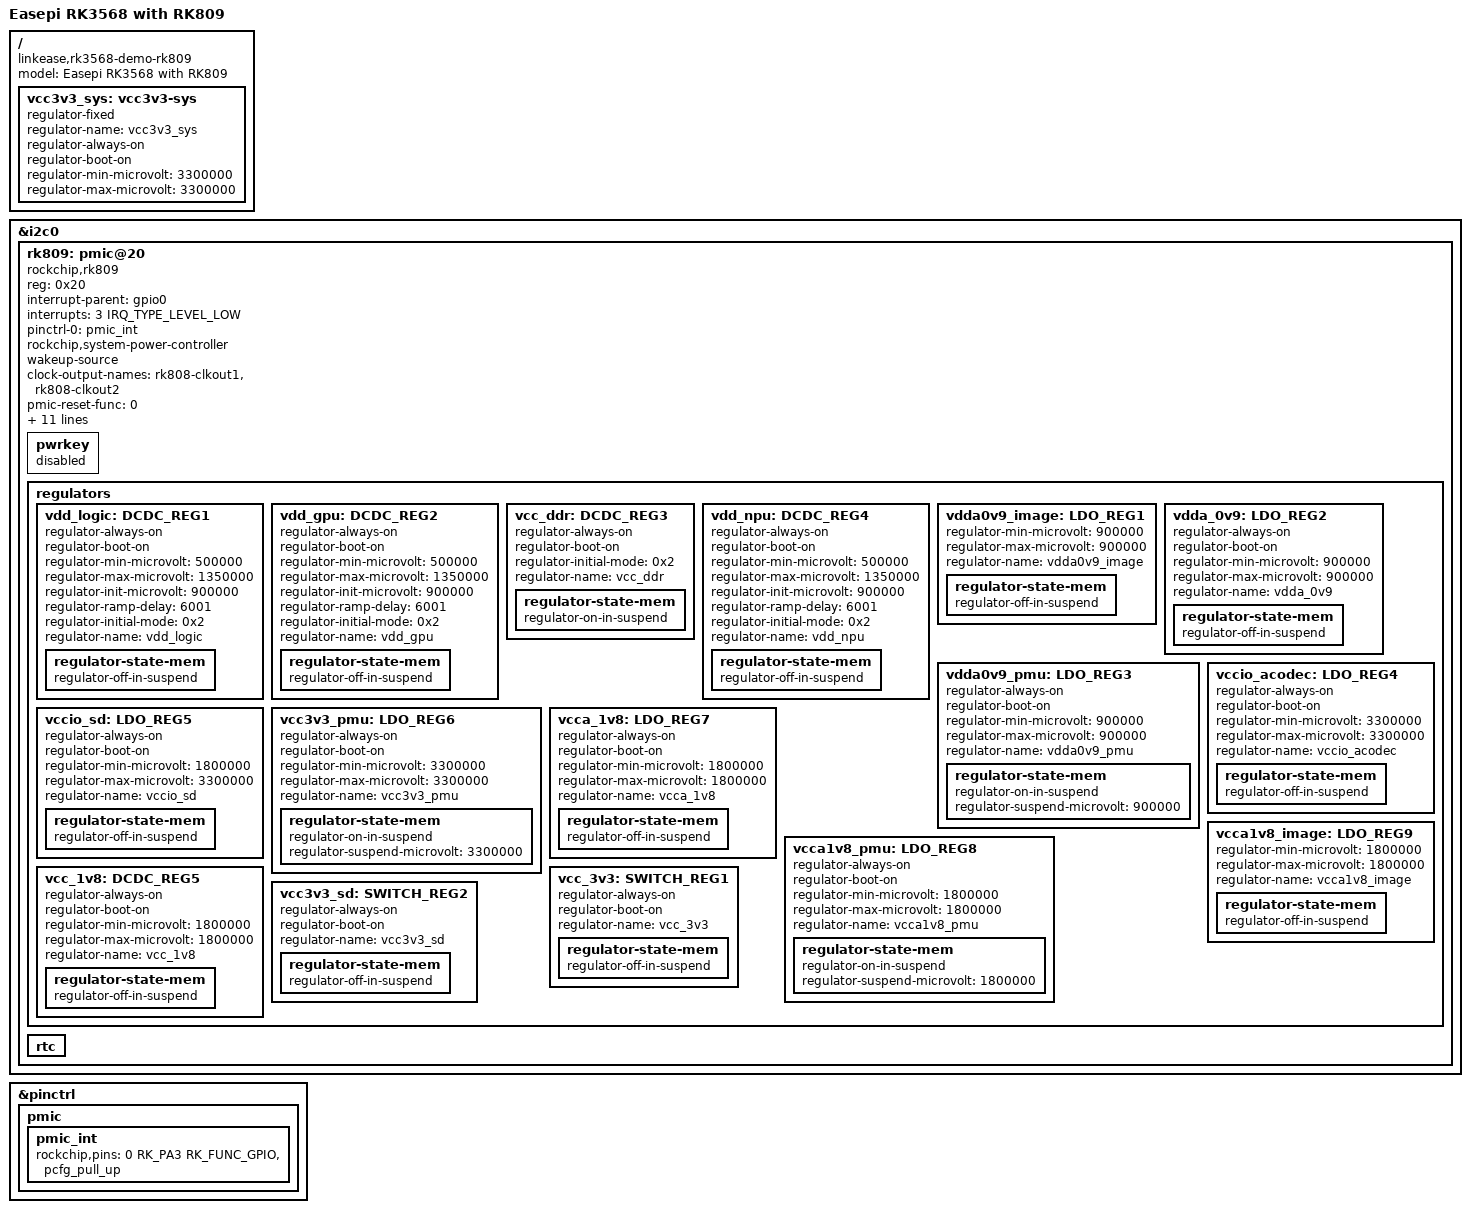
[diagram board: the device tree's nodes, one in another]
// SPDX-License-Identifier: (GPL-2.0+ OR MIT)

/dts-v1/;
#include "rk3568-easepi.dts"

/ {
	model = "Easepi RK3568 with RK809";
	compatible = "linkease,rk3568-demo-rk809", "rockchip,rk3568";

	vcc3v3_sys: vcc3v3-sys {
		compatible = "regulator-fixed";
		regulator-name = "vcc3v3_sys";
		regulator-always-on;
		regulator-boot-on;
		regulator-min-microvolt = <3300000>;
		regulator-max-microvolt = <3300000>;
	};
};


&i2c0 {
	status = "okay";

	rk809: pmic@20 {
		compatible = "rockchip,rk809";
		reg = <0x20>;
		interrupt-parent = <&gpio0>;
		interrupts = <3 IRQ_TYPE_LEVEL_LOW>;

		pinctrl-names = "default";
		pinctrl-0 = <&pmic_int>;

		rockchip,system-power-controller;
		wakeup-source;
		#clock-cells = <1>;
		clock-output-names = "rk808-clkout1", "rk808-clkout2";
		//fb-inner-reg-idxs = <2>;
		/* 1: rst regs (default in codes), 0: rst the pmic */
		pmic-reset-func = <0>;
		/* not save the PMIC_POWER_EN register in uboot */
		not-save-power-en = <1>;
		long-press-off-time-sec = <10>;

		vcc1-supply = <&vcc3v3_sys>;
		vcc2-supply = <&vcc3v3_sys>;
		vcc3-supply = <&vcc3v3_sys>;
		vcc4-supply = <&vcc3v3_sys>;
		vcc5-supply = <&vcc3v3_sys>;
		vcc6-supply = <&vcc3v3_sys>;
		vcc7-supply = <&vcc3v3_sys>;
		vcc8-supply = <&vcc3v3_sys>;
		vcc9-supply = <&vcc3v3_sys>;

		status = "okay";

		pwrkey {
			status = "disabled";
		};

		regulators {
			vdd_logic: DCDC_REG1 {
				regulator-always-on;
				regulator-boot-on;
				regulator-min-microvolt = <500000>;
				regulator-max-microvolt = <1350000>;
				regulator-init-microvolt = <900000>;
				regulator-ramp-delay = <6001>;
				regulator-initial-mode = <0x2>;
				regulator-name = "vdd_logic";
				regulator-state-mem {
					regulator-off-in-suspend;
				};
			};

			vdd_gpu: DCDC_REG2 {
				regulator-always-on;
				regulator-boot-on;
				regulator-min-microvolt = <500000>;
				regulator-max-microvolt = <1350000>;
				regulator-init-microvolt = <900000>;
				regulator-ramp-delay = <6001>;
				regulator-initial-mode = <0x2>;
				regulator-name = "vdd_gpu";
				regulator-state-mem {
					regulator-off-in-suspend;
				};
			};

			vcc_ddr: DCDC_REG3 {
				regulator-always-on;
				regulator-boot-on;
				regulator-initial-mode = <0x2>;
				regulator-name = "vcc_ddr";
				regulator-state-mem {
					regulator-on-in-suspend;
				};
			};

			vdd_npu: DCDC_REG4 {
				regulator-always-on;
				regulator-boot-on;
				regulator-min-microvolt = <500000>;
				regulator-max-microvolt = <1350000>;
				regulator-init-microvolt = <900000>;
				regulator-ramp-delay = <6001>;
				regulator-initial-mode = <0x2>;
				regulator-name = "vdd_npu";
				regulator-state-mem {
					regulator-off-in-suspend;
				};
			};

			vdda0v9_image: LDO_REG1 {
				regulator-min-microvolt = <900000>;
				regulator-max-microvolt = <900000>;
				regulator-name = "vdda0v9_image";
				regulator-state-mem {
					regulator-off-in-suspend;
				};
			};

			vdda_0v9: LDO_REG2 {
				regulator-always-on;
				regulator-boot-on;
				regulator-min-microvolt = <900000>;
				regulator-max-microvolt = <900000>;
				regulator-name = "vdda_0v9";
				regulator-state-mem {
					regulator-off-in-suspend;
				};
			};

			vdda0v9_pmu: LDO_REG3 {
				regulator-always-on;
				regulator-boot-on;
				regulator-min-microvolt = <900000>;
				regulator-max-microvolt = <900000>;
				regulator-name = "vdda0v9_pmu";
				regulator-state-mem {
					regulator-on-in-suspend;
					regulator-suspend-microvolt = <900000>;
				};
			};

			vccio_acodec: LDO_REG4 {
				regulator-always-on;
				regulator-boot-on;
				regulator-min-microvolt = <3300000>;
				regulator-max-microvolt = <3300000>;
				regulator-name = "vccio_acodec";
				regulator-state-mem {
					regulator-off-in-suspend;
				};
			};

			vccio_sd: LDO_REG5 {
				regulator-always-on;
				regulator-boot-on;
				regulator-min-microvolt = <1800000>;
				regulator-max-microvolt = <3300000>;
				regulator-name = "vccio_sd";
				regulator-state-mem {
					regulator-off-in-suspend;
				};
			};

			vcc3v3_pmu: LDO_REG6 {
				regulator-always-on;
				regulator-boot-on;
				regulator-min-microvolt = <3300000>;
				regulator-max-microvolt = <3300000>;
				regulator-name = "vcc3v3_pmu";
				regulator-state-mem {
					regulator-on-in-suspend;
					regulator-suspend-microvolt = <3300000>;
				};
			};

			vcca_1v8: LDO_REG7 {
				regulator-always-on;
				regulator-boot-on;
				regulator-min-microvolt = <1800000>;
				regulator-max-microvolt = <1800000>;
				regulator-name = "vcca_1v8";
				regulator-state-mem {
					regulator-off-in-suspend;
				};
			};

			vcca1v8_pmu: LDO_REG8 {
				regulator-always-on;
				regulator-boot-on;
				regulator-min-microvolt = <1800000>;
				regulator-max-microvolt = <1800000>;
				regulator-name = "vcca1v8_pmu";
				regulator-state-mem {
					regulator-on-in-suspend;
					regulator-suspend-microvolt = <1800000>;
				};
			};

			vcca1v8_image: LDO_REG9 {
				regulator-min-microvolt = <1800000>;
				regulator-max-microvolt = <1800000>;
				regulator-name = "vcca1v8_image";
				regulator-state-mem {
					regulator-off-in-suspend;
				};
			};

			vcc_1v8: DCDC_REG5 {
				regulator-always-on;
				regulator-boot-on;
				regulator-min-microvolt = <1800000>;
				regulator-max-microvolt = <1800000>;
				regulator-name = "vcc_1v8";
				regulator-state-mem {
					regulator-off-in-suspend;
				};
			};

			vcc_3v3: SWITCH_REG1 {
				regulator-always-on;
				regulator-boot-on;
				regulator-name = "vcc_3v3";
				regulator-state-mem {
					regulator-off-in-suspend;
				};
			};

			vcc3v3_sd: SWITCH_REG2 {
				regulator-always-on;
				regulator-boot-on;
				regulator-name = "vcc3v3_sd";
				regulator-state-mem {
					regulator-off-in-suspend;
				};
			};
		};

		rtc {
			status = "okay";
		};
	};
};

&pinctrl {
	pmic {
		pmic_int: pmic_int {
			rockchip,pins =
				<0 RK_PA3 RK_FUNC_GPIO &pcfg_pull_up>;
		};
	};
};
